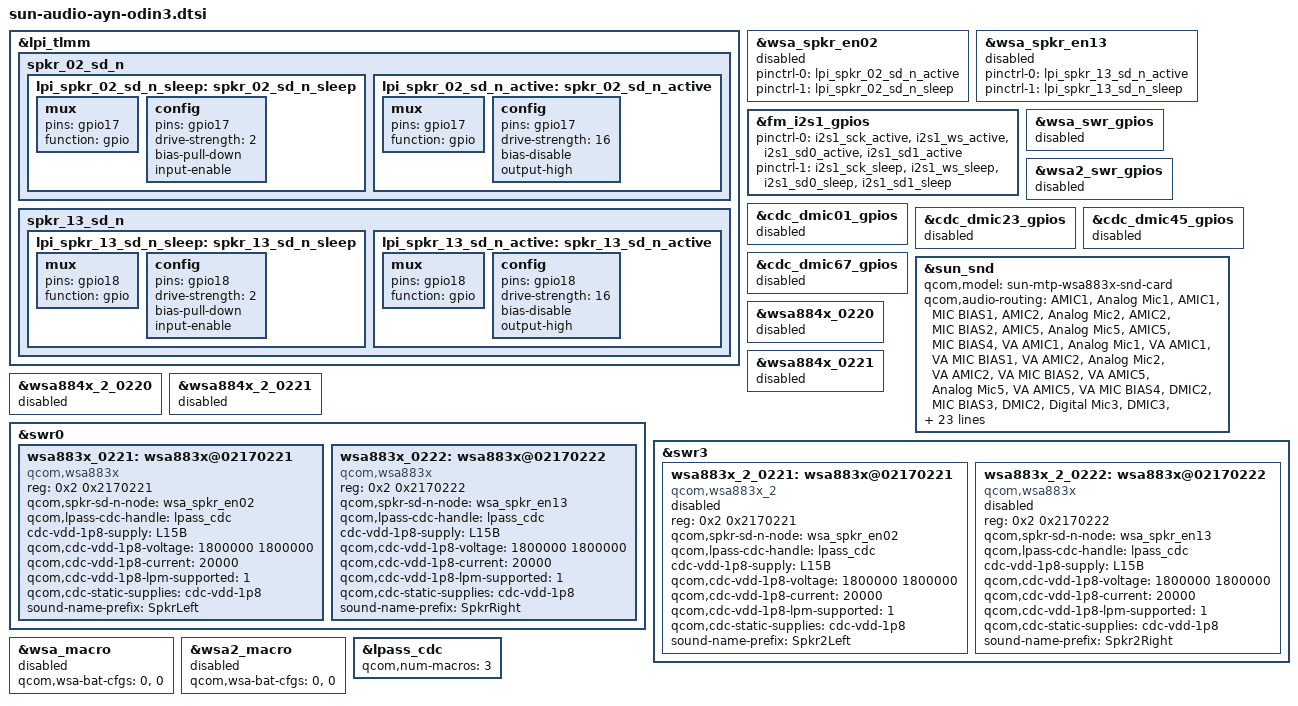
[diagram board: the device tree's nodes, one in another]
#include "../../qcom/audio/sun-audio-overlay.dtsi"

&lpi_tlmm {
	spkr_02_sd_n {
		lpi_spkr_02_sd_n_sleep: spkr_02_sd_n_sleep {
			mux {
				pins = "gpio17";
				function = "gpio";
			};

			config {
				pins = "gpio17";
				drive-strength = <2>;   /* 2 mA */
				bias-pull-down;
				input-enable;
			};
		};

		lpi_spkr_02_sd_n_active: spkr_02_sd_n_active {
			mux {
				pins = "gpio17";
				function = "gpio";
			};

			config {
				pins = "gpio17";
				drive-strength = <16>;   /* 16 mA */
				bias-disable;
				output-high;
			};
		};
	};

	spkr_13_sd_n {
		lpi_spkr_13_sd_n_sleep: spkr_13_sd_n_sleep {
			mux {
				pins = "gpio18";
				function = "gpio";
			};

			config {
				pins = "gpio18";
				drive-strength = <2>;   /* 2 mA */
				bias-pull-down;
				input-enable;
			};
		};

		lpi_spkr_13_sd_n_active: spkr_13_sd_n_active {
			mux {
				pins = "gpio18";
				function = "gpio";
			};

			config {
				pins = "gpio18";
				drive-strength = <16>;   /* 16 mA */
				bias-disable;
				output-high;
			};
		};
	};
};

&wsa_spkr_en02 {
	status = "disabled";
	pinctrl-0 = <&lpi_spkr_02_sd_n_active>;
	pinctrl-1 = <&lpi_spkr_02_sd_n_sleep>;
};

&wsa_spkr_en13 {
	status = "disabled";
	pinctrl-0 = <&lpi_spkr_13_sd_n_active>;
	pinctrl-1 = <&lpi_spkr_13_sd_n_sleep>;
};

&fm_i2s1_gpios {
	status = "ok";

	pinctrl-0 = <&i2s1_sck_active &i2s1_ws_active
			&i2s1_sd0_active &i2s1_sd1_active>;
	pinctrl-1 = <&i2s1_sck_sleep &i2s1_ws_sleep
			&i2s1_sd0_sleep &i2s1_sd1_sleep>;
};

&wsa_swr_gpios {
	status = "disabled";
};

&wsa2_swr_gpios {
	status = "disabled";
};

&cdc_dmic01_gpios {
	status = "disabled";
};

&cdc_dmic23_gpios {
	status = "disabled";
};

&cdc_dmic45_gpios {
	status = "disabled";
};

&cdc_dmic67_gpios {
	status = "disabled";
};

&sun_snd {
	qcom,model = "sun-qrd-snd-card";

	qcom,audio-routing = 
		"AMIC1", "Analog Mic1",
		"AMIC1", "MIC BIAS1",
		"AMIC2", "Analog Mic2",
		"AMIC2", "MIC BIAS2",
		"AMIC5", "Analog Mic5",
		"AMIC5", "MIC BIAS4",
		"VA AMIC1", "Analog Mic1",
		"VA AMIC1", "VA MIC BIAS1",
		"VA AMIC2", "Analog Mic2",
		"VA AMIC2", "VA MIC BIAS2",
		"VA AMIC5", "Analog Mic5",
		"VA AMIC5", "VA MIC BIAS4",
		"DMIC2", "MIC BIAS3",
		"DMIC2", "Digital Mic3",
		"DMIC3", "MIC BIAS3",
		"DMIC3", "Digital Mic3",
		"IN1_HPHL", "HPHL_OUT",
		"IN2_HPHR", "HPHR_OUT",
		"IN3_EAR", "AUX_OUT",
		"RX_TX DEC0_INP", "TX DEC0 MUX", 
		"RX_TX DEC1_INP", "TX DEC1 MUX",
		"RX_TX DEC2_INP", "TX DEC2 MUX",
		"RX_TX DEC3_INP", "TX DEC3 MUX",
		"TX SWR_INPUT", "WCD_TX_OUTPUT",
		"VA SWR_INPUT", "VA_SWR_CLK",
		"VA SWR_INPUT", "WCD_TX_OUTPUT",
		"VA_AIF1 CAP", "VA_SWR_CLK",
		"VA_AIF2 CAP", "VA_SWR_CLK",
		"VA_AIF3 CAP", "VA_SWR_CLK",
		"VA DMIC2", "VA MIC BIAS3",
		"VA DMIC3", "VA MIC BIAS3";

	/delete-property/ qcom,cdc-dmic01-gpios;
	/delete-property/ qcom,cdc-dmic23-gpios;
	/delete-property/ qcom,cdc-dmic45-gpios;

	qcom,model = "sun-mtp-wsa883x-snd-card";
	qcom,sec-mi2s-gpios = <&fm_i2s1_gpios>;
	asoc-codec  = <&stub_codec>, <&lpass_cdc>,
				<&wcd939x_codec>, <&swr_haptics>;
	asoc-codec-names = "msm-stub-codec.1", "lpass-cdc",
				"wcd939x_codec", "swr-haptics";
	qcom,wsa-max-devs = <0>;

	qcom,msm-mbhc-usbc-audio-supported = <1>;
	qcom,msm-mbhc-hphl-swh = <0>;
	qcom,msm-mbhc-gnd-swh = <0>;
	qcom,wcn-bt-ext = <1>;
	qcom,wcd-disable-legacy-surge;
	wcd939x-i2c-handle = <&wcd_usbss>;
};

&wsa884x_0220 {
	status = "disabled";
};

&wsa884x_0221 {
	status = "disabled";
};

&wsa884x_2_0220 {
	status = "disabled";
};

&wsa884x_2_0221 {
	status = "disabled";
};

&swr0 {
	wsa883x_0221: wsa883x@02170221 {
		compatible = "qcom,wsa883x";
		reg = <0x2 0x2170221>;
		qcom,spkr-sd-n-node = <&wsa_spkr_en02>;
		qcom,lpass-cdc-handle = <&lpass_cdc>;
		cdc-vdd-1p8-supply = <&L15B>;
		qcom,cdc-vdd-1p8-voltage = <1800000 1800000>;
		qcom,cdc-vdd-1p8-current = <20000>;
		qcom,cdc-vdd-1p8-lpm-supported = <1>;
		qcom,cdc-static-supplies = "cdc-vdd-1p8";
		sound-name-prefix = "SpkrLeft";
	};

	wsa883x_0222: wsa883x@02170222 {
		compatible = "qcom,wsa883x";
		reg = <0x2 0x2170222>;
		qcom,spkr-sd-n-node = <&wsa_spkr_en13>;
		qcom,lpass-cdc-handle = <&lpass_cdc>;
		cdc-vdd-1p8-supply = <&L15B>;
		qcom,cdc-vdd-1p8-voltage = <1800000 1800000>;
		qcom,cdc-vdd-1p8-current = <20000>;
		qcom,cdc-vdd-1p8-lpm-supported = <1>;
		qcom,cdc-static-supplies = "cdc-vdd-1p8";
		sound-name-prefix = "SpkrRight";
	};
};

&swr3 {
	wsa883x_2_0221: wsa883x@02170221 {
		compatible = "qcom,wsa883x_2";
		reg = <0x2 0x2170221>;
		qcom,spkr-sd-n-node = <&wsa_spkr_en02>;
		qcom,lpass-cdc-handle = <&lpass_cdc>;
		cdc-vdd-1p8-supply = <&L15B>;
		qcom,cdc-vdd-1p8-voltage = <1800000 1800000>;
		qcom,cdc-vdd-1p8-current = <20000>;
		qcom,cdc-vdd-1p8-lpm-supported = <1>;
		qcom,cdc-static-supplies = "cdc-vdd-1p8";
		sound-name-prefix = "Spkr2Left";
		status = "disabled";
	};

	wsa883x_2_0222: wsa883x@02170222 {
		compatible = "qcom,wsa883x";
		reg = <0x2 0x2170222>;
		qcom,spkr-sd-n-node = <&wsa_spkr_en13>;
		qcom,lpass-cdc-handle = <&lpass_cdc>;
		cdc-vdd-1p8-supply = <&L15B>;
		qcom,cdc-vdd-1p8-voltage = <1800000 1800000>;
		qcom,cdc-vdd-1p8-current = <20000>;
		qcom,cdc-vdd-1p8-lpm-supported = <1>;
		qcom,cdc-static-supplies = "cdc-vdd-1p8";
		sound-name-prefix = "Spkr2Right";
		status = "disabled";
	};
};

&wsa_macro {
	status = "disabled";
	qcom,wsa-bat-cfgs= <0>, <0>;
};

&wsa2_macro {
	status = "disabled";
	qcom,wsa-bat-cfgs= <0>, <0>;
};

&lpass_cdc {
	qcom,num-macros = <3>;
};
